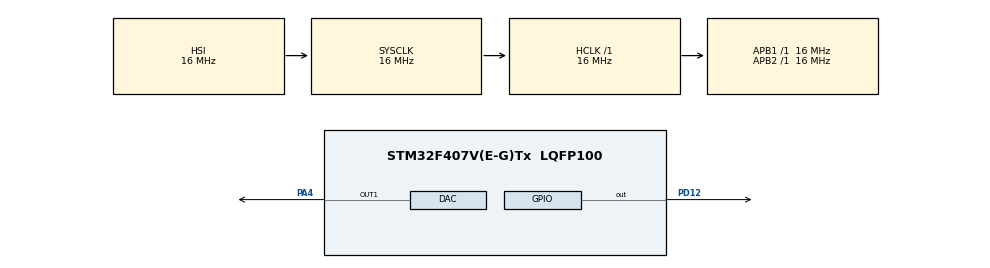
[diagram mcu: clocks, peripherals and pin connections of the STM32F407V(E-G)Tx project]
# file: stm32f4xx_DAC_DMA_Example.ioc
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DAC.DAC_Trigger=DAC_TRIGGER_T2_TRGO
Dma.DAC1.0.Direction=DMA_MEMORY_TO_PERIPH
Dma.DAC1.0.FIFOMode=DMA_FIFOMODE_DISABLE
Dma.DAC1.0.Instance=DMA1_Stream5
Dma.DAC1.0.MemDataAlignment=DMA_MDATAALIGN_HALFWORD
Dma.DAC1.0.MemInc=DMA_MINC_ENABLE
Dma.DAC1.0.Mode=DMA_CIRCULAR
Dma.DAC1.0.PeriphDataAlignment=DMA_PDATAALIGN_HALFWORD
Dma.DAC1.0.PeriphInc=DMA_PINC_DISABLE
Dma.DAC1.0.Priority=DMA_PRIORITY_LOW
Dma.Request0=DAC1
Mcu.Family=STM32F4
Mcu.Name=STM32F407V(E-G)Tx
Mcu.Package=LQFP100
NVIC.DMA1_Stream5_IRQn=true\:0\:0\:false\:false\:true\:false\:true
NVIC.PriorityGroup=NVIC_PRIORITYGROUP_4
PA13.Mode=Serial_Wire
PA13.Signal=SYS_JTMS-SWDIO
PA14.Mode=Serial_Wire
PA14.Signal=SYS_JTCK-SWCLK
PA4.Signal=COMP_DAC1_group
PD12.Signal=GPIO_Output
PH0-OSC_IN.Mode=HSE-External-Oscillator
PH0-OSC_IN.Signal=RCC_OSC_IN
PH1-OSC_OUT.Mode=HSE-External-Oscillator
PH1-OSC_OUT.Signal=RCC_OSC_OUT
ProjectManager.HeapSize=0x200
ProjectManager.StackSize=0x400
ProjectManager.TargetToolchain=STM32CubeIDE
RCC.AHBFreq_Value=16000000
RCC.APB1Freq_Value=16000000
RCC.APB2Freq_Value=16000000
RCC.CortexFreq_Value=16000000
RCC.HSE_VALUE=25000000
RCC.HSI_VALUE=16000000
RCC.LSE_VALUE=32768
RCC.SYSCLKFreq_VALUE=16000000
RCC.VCOOutputFreq_Value=192000000
SH.COMP_DAC1_group.0=DAC_OUT1,DAC_OUT1
TIM2.Period=999
TIM2.Prescaler=15999
TIM2.TIM_MasterOutputTrigger=TIM_TRGO_UPDATE
VP_TIM2_VS_ClockSourceINT.Mode=Internal
board=custom

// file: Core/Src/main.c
/* USER CODE BEGIN Header */
/**
  ******************************************************************************
  * @file           : main.c
  * @brief          : Main program body
  ******************************************************************************
  * @attention
  *
  * <h2><center>&copy; Copyright (c) 2020 STMicroelectronics.
  * All rights reserved.</center></h2>
  *
  * This software component is licensed by ST under BSD 3-Clause license,
  * the "License"; You may not use this file except in compliance with the
  * License. You may obtain a copy of the License at:
  *                        opensource.org/licenses/BSD-3-Clause
  *
  ******************************************************************************
  */
/* USER CODE END Header */
#include "main.h"

DAC_HandleTypeDef hdac;
DMA_HandleTypeDef hdma_dac1;

TIM_HandleTypeDef htim2;

/* USER CODE BEGIN PV */
const uint16_t OndaSeno[32] = {2047, 1648, 1264, 910, 600,  345,
                   156, 39,  0,  39,  156,  345,
                    600, 910, 1264, 1648, 2048, 2447,
                    2831, 3185, 3495, 3750, 3939, 4056,
                    4095, 4056, 3939, 3750, 3495, 3185,
                    2831, 2447};
/* USER CODE END PV */

void SystemClock_Config(void);
static void MX_GPIO_Init(void);
static void MX_DMA_Init(void);
static void MX_DAC_Init(void);
static void MX_TIM2_Init(void);

int main(void)
{

  /* MCU Configuration--------------------------------------------------------*/

  /* Reset of all peripherals, Initializes the Flash interface and the Systick. */
  HAL_Init();

  /* Configure the system clock */
  SystemClock_Config();

  /* Initialize all configured peripherals */
  MX_GPIO_Init();
  MX_DMA_Init();
  MX_DAC_Init();
  MX_TIM2_Init();

  /* Infinite loop */
  /* USER CODE BEGIN WHILE */

    /* la frecuencia con la que cambia el valor del DAC lo establece el TIMER2
     *  para este ejemplo  esta configurado a 1 hz para que puedas apreciarlo
     *  con un multimetro NOTA: la rutina dentro del while no tiene nada que ver
     *  la frecuencia de conversion del DAC.
     */
    HAL_TIM_Base_Start(&htim2); // inicia el timer2
    HAL_DAC_Start(&hdac,DAC_CHANNEL_1); // inicia el DAC en el canal 1
    /* inicia DMA y asigna nuestra matriz a DMA */
    HAL_DAC_Start_DMA(&hdac, DAC_CHANNEL_1, (uint32_t*)OndaSeno, 32, DAC_ALIGN_12B_R);

  while (1)
  {
      HAL_GPIO_TogglePin(GPIOD, GPIO_PIN_12);
      HAL_Delay(500);
    /* USER CODE END WHILE */

  }
}

void SystemClock_Config(void)
{
  RCC_OscInitTypeDef RCC_OscInitStruct = {0};
  RCC_ClkInitTypeDef RCC_ClkInitStruct = {0};

  /** Configure the main internal regulator output voltage
  */
  __HAL_RCC_PWR_CLK_ENABLE();
  __HAL_PWR_VOLTAGESCALING_CONFIG(PWR_REGULATOR_VOLTAGE_SCALE1);
  /** Initializes the RCC Oscillators according to the specified parameters
  * in the RCC_OscInitTypeDef structure.
  */
  RCC_OscInitStruct.OscillatorType = RCC_OSCILLATORTYPE_HSI;
  RCC_OscInitStruct.HSIState = RCC_HSI_ON;
  RCC_OscInitStruct.HSICalibrationValue = RCC_HSICALIBRATION_DEFAULT;
  RCC_OscInitStruct.PLL.PLLState = RCC_PLL_NONE;
  if (HAL_RCC_OscConfig(&RCC_OscInitStruct) != HAL_OK)
  {
    Error_Handler();
  }
  /** Initializes the CPU, AHB and APB buses clocks
  */
  RCC_ClkInitStruct.ClockType = RCC_CLOCKTYPE_HCLK|RCC_CLOCKTYPE_SYSCLK
                              |RCC_CLOCKTYPE_PCLK1|RCC_CLOCKTYPE_PCLK2;
  RCC_ClkInitStruct.SYSCLKSource = RCC_SYSCLKSOURCE_HSI;
  RCC_ClkInitStruct.AHBCLKDivider = RCC_SYSCLK_DIV1;
  RCC_ClkInitStruct.APB1CLKDivider = RCC_HCLK_DIV1;
  RCC_ClkInitStruct.APB2CLKDivider = RCC_HCLK_DIV1;

  if (HAL_RCC_ClockConfig(&RCC_ClkInitStruct, FLASH_LATENCY_0) != HAL_OK)
  {
    Error_Handler();
  }
}

static void MX_DAC_Init(void)
{

  DAC_ChannelConfTypeDef sConfig = {0};

  /** DAC Initialization
  */
  hdac.Instance = DAC;
  if (HAL_DAC_Init(&hdac) != HAL_OK)
  {
    Error_Handler();
  }
  /** DAC channel OUT1 config
  */
  sConfig.DAC_Trigger = DAC_TRIGGER_T2_TRGO;
  sConfig.DAC_OutputBuffer = DAC_OUTPUTBUFFER_ENABLE;
  if (HAL_DAC_ConfigChannel(&hdac, &sConfig, DAC_CHANNEL_1) != HAL_OK)
  {
    Error_Handler();
  }

}

static void MX_TIM2_Init(void)
{

  TIM_ClockConfigTypeDef sClockSourceConfig = {0};
  TIM_MasterConfigTypeDef sMasterConfig = {0};

  htim2.Instance = TIM2;
  htim2.Init.Prescaler = 15999;
  htim2.Init.CounterMode = TIM_COUNTERMODE_UP;
  htim2.Init.Period = 999;
  htim2.Init.ClockDivision = TIM_CLOCKDIVISION_DIV1;
  htim2.Init.AutoReloadPreload = TIM_AUTORELOAD_PRELOAD_DISABLE;
  if (HAL_TIM_Base_Init(&htim2) != HAL_OK)
  {
    Error_Handler();
  }
  sClockSourceConfig.ClockSource = TIM_CLOCKSOURCE_INTERNAL;
  if (HAL_TIM_ConfigClockSource(&htim2, &sClockSourceConfig) != HAL_OK)
  {
    Error_Handler();
  }
  sMasterConfig.MasterOutputTrigger = TIM_TRGO_UPDATE;
  sMasterConfig.MasterSlaveMode = TIM_MASTERSLAVEMODE_DISABLE;
  if (HAL_TIMEx_MasterConfigSynchronization(&htim2, &sMasterConfig) != HAL_OK)
  {
    Error_Handler();
  }

}

static void MX_DMA_Init(void)
{

  /* DMA controller clock enable */
  __HAL_RCC_DMA1_CLK_ENABLE();

  /* DMA interrupt init */
  /* DMA1_Stream5_IRQn interrupt configuration */
  HAL_NVIC_SetPriority(DMA1_Stream5_IRQn, 0, 0);
  HAL_NVIC_EnableIRQ(DMA1_Stream5_IRQn);

}

static void MX_GPIO_Init(void)
{
  GPIO_InitTypeDef GPIO_InitStruct = {0};

  /* GPIO Ports Clock Enable */
  __HAL_RCC_GPIOH_CLK_ENABLE();
  __HAL_RCC_GPIOA_CLK_ENABLE();
  __HAL_RCC_GPIOD_CLK_ENABLE();

  /*Configure GPIO pin Output Level */
  HAL_GPIO_WritePin(GPIOD, GPIO_PIN_12, GPIO_PIN_RESET);

  /*Configure GPIO pin : PD12 */
  GPIO_InitStruct.Pin = GPIO_PIN_12;
  GPIO_InitStruct.Mode = GPIO_MODE_OUTPUT_PP;
  GPIO_InitStruct.Pull = GPIO_NOPULL;
  GPIO_InitStruct.Speed = GPIO_SPEED_FREQ_LOW;
  HAL_GPIO_Init(GPIOD, &GPIO_InitStruct);

}

void Error_Handler(void)
{
}

/************************ (C) COPYRIGHT STMicroelectronics *****END OF FILE****/
